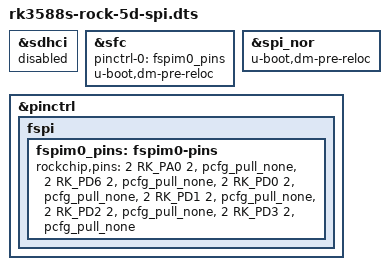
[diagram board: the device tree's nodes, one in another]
// SPDX-License-Identifier: (GPL-2.0+ OR MIT)
/*
 * Copyright (c) 2024 Rockchip Electronics Co., Ltd
 *
 */

/dts-v1/;
#include "rk3588s-rock-5d.dts"

&sdhci {
	status = "disabled";
};

&sfc {
	status = "okay";
	pinctrl-names = "default";
	pinctrl-0 = <&fspim0_pins>;
	u-boot,dm-pre-reloc;
};

&spi_nor {
	status = "okay";
	u-boot,dm-pre-reloc;
};

&pinctrl {

	/delete-node/ fspi;
	fspi {
		u-boot,dm-spl;
		fspim0_pins: fspim0-pins {
			u-boot,dm-spl;
			rockchip,pins =
				/* fspi_clk_m0 */
				<2 RK_PA0 2 &pcfg_pull_none>,
				/* fspi_cs0n_m0 */
				<2 RK_PD6 2 &pcfg_pull_none>,
				/* fspi_d0_m0 */
				<2 RK_PD0 2 &pcfg_pull_none>,
				/* fspi_d1_m0 */
				<2 RK_PD1 2 &pcfg_pull_none>,
				/* fspi_d2_m0 */
				<2 RK_PD2 2 &pcfg_pull_none>,
				/* fspi_d3_m0 */
				<2 RK_PD3 2 &pcfg_pull_none>;
		};
	};
};
